# CONTROLSS_DMAXBAR_CONTROLSS_DMAXBAR register map
Vendor: Texas Instruments
Peripheral module from a debugger description file (folder AM263).
Registers are 8-bit, read-write, reset 0x0 unless marked. A register's access mark holds for its fields unless they carry their own. Offsets are as the file gives them; lines under a group give offsets from that group; [hi:lo] are bit positions; {n}, {i} and the like mark numbered series; 'fields as' and 'values as' point back to an identical list; <NAME> marks a mode.

## CONTROLSS_DMAXBAR_CONTROLSS_DMAXBAR
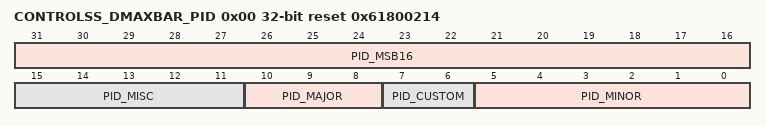
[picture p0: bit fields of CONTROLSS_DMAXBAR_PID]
0x00 CONTROLSS_DMAXBAR_PID 32-bit ro reset 0x61800214
  [31:16] PID_MSB16 — Not Defined
  [15:11] PID_MISC — Not Defined
  [10:8] PID_MAJOR — Not Defined
  [7:6] PID_CUSTOM — Not Defined
  [5:0] PID_MINOR — Not Defined
{0x100+0x40*i} CONTROLSS_DMAXBAR_DMAXBAR{i}_GSEL (i=0..15)
  [2:0] GSEL — Select input source:0: G0 selected..5: G5 selected
{0x104+0x40*i} CONTROLSS_DMAXBAR_DMAXBAR{i}_G0 (i=0..15)
  [4:0] SEL — ETPWM SOCA to corresponding xbar1: PWMx.SOCA is selected0: PWMx.SOCA is de-selected
{0x108+0x40*i} CONTROLSS_DMAXBAR_DMAXBAR{i}_G1 (i=0..15)
  [4:0] SEL — ETPWM SOCB to corresponding xbar1: PWMx.SOCB is selected0: PWMx.SOCB is de-selected
{0x10C+0x40*i} CONTROLSS_DMAXBAR_DMAXBAR{i}_G2 (i=0..15)
  [4:0] SEL — ADC DMA requests to corresponding xbar0: ADC0.INT11: ADC0.INT22: ADC0.INT33: ADC0.INT44: ADC0.EVTINT5: ADC1.INT16: ADC1.INT27: ADC1.INT38: ADC1.INT49: ADC1.EVTINT10: ADC2.INT111: ADC2.INT212: ADC2.INT313: ADC2.INT414: ADC2.EVTINT15: ADC3.INT116: ADC3.INT217: ADC3.INT318: ADC3.INT419: ADC3.EVTINT20: ADC4.INT121: ADC4.INT222: ADC4.INT323: ADC4.INT424: ADC4.EVTINT
{0x110+0x40*i} CONTROLSS_DMAXBAR_DMAXBAR{i}_G3 (i=0..15)
  [3:0] SEL — FSI DMA requests to corresponding xbar0: FSIRX0.RX_DMA_EVT1; FSIRX0_DMATRIG12: FSIRX0_DMATRIG23: FSIRX1.RX_DMA_EVT4; FSIRX1_DMATRIG15: FSIRX1_DMATRIG26: FSIRX2.RX_DMA_EVT7; FSIRX2_DMATRIG18: FSIRX2_DMATRIG29: FSIRX3.RX_DMA_EVT10; FSIRX3_DMATRIG111: FSIRX3_DMATRIG212: FSITX0.TX_DMA_EVT13: FSITX1.TX_DMA_EVT14: FSITX2.TX_DMA_EVT15: FSITX3.TX_DMA_EVT
{0x114+0x40*i} CONTROLSS_DMAXBAR_DMAXBAR{i}_G4 (i=0..15)
  [2:0] SEL — SDFM DMA requests to corresponding xbar0: SD0.FILT1.DRINT1: SD0.FILT2.DRINT2: SD0.FILT3.DRINT3: SD0.FILT4.DRINT4: SD1.FILT1.DRINT5: SD1.FILT2.DRINT6: SD1.FILT3.DRINT7: SD1.FILT4.DRINT
{0x118+0x40*i} CONTROLSS_DMAXBAR_DMAXBAR{i}_G5 (i=0..15)
  [3:0] SEL — ECAP DMA requests to corresponding xbar0: ECAP0.DMA_INT1: ECAP1.DMA_INT2: ECAP2.DMA_INT3: ECAP3.DMA_INT4: ECAP4.DMA_INT5: ECAP5.DMA_INT6: ECAP6.DMA_INT7: ECAP7.DMA_INT8: ECAP8.DMA_INT9: ECAP9.DMA_INT
